# ATSAME54N19A device description
Architecture: CORTEX-M4; Family: SAMD; Series: SAME54
Registers are 32-bit, read-write, reset 0x0 unless marked. A register's access mark holds for its fields unless they carry their own. Offsets are from the block's base; [hi:lo] are bit positions; {n}, {i} and the like mark numbered series; 'fields as' and 'values as' point back to an identical list.

## CAN — Control Area Network
Instances: CAN0 0x42000000, CAN1 0x42000400
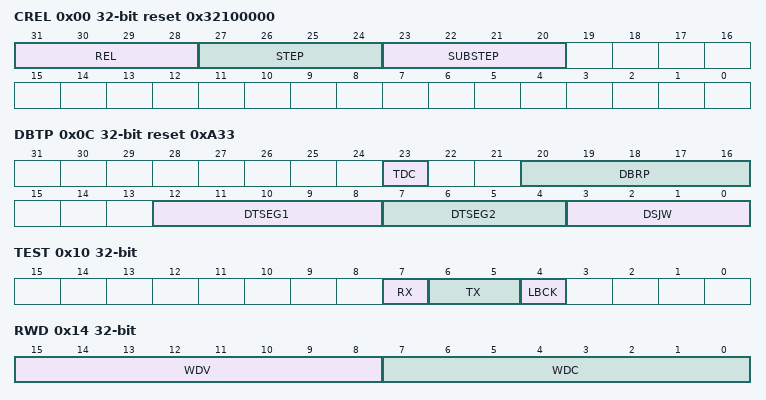
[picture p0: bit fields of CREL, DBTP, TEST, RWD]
0x00 CREL ro reset 0x32100000 — Core Release
  [31:28] REL — Core Release
  [27:24] STEP — Step of Core Release
  [23:20] SUBSTEP — Sub-step of Core Release
0x04 ENDN ro reset 0x87654321 — Endian
  [31:0] ETV — Endianness Test Value
0x08 MRCFG reset 0x2 — Message RAM Configuration
  [1:0] QOS — Quality of Service
    0=DISABLE (Background (no sensitive operation)); 1=LOW (Sensitive Bandwidth); 2=MEDIUM (Sensitive Latency); 3=HIGH (Critical Latency)
0x0C DBTP reset 0xA33 — Fast Bit Timing and Prescaler
  [23] TDC — Tranceiver Delay Compensation
  [20:16] DBRP — Data Baud Rate Prescaler
  [12:8] DTSEG1 — Data time segment before sample point
  [7:4] DTSEG2 — Data time segment after sample point
  [3:0] DSJW — Data (Re)Synchronization Jump Width
0x10 TEST
  [7] RX — Receive Pin
  [6:5] TX — Control of Transmit Pin
    0=CORE (TX controlled by CAN core); 1=SAMPLE (TX monitoring sample point); 2=DOMINANT (Dominant (0) level at pin CAN_TX); 3=RECESSIVE (Recessive (1) level at pin CAN_TX)
  [4] LBCK — Loop Back Mode
0x14 RWD — RAM Watchdog
  [15:8] WDV — Watchdog Value
  [7:0] WDC — Watchdog Configuration
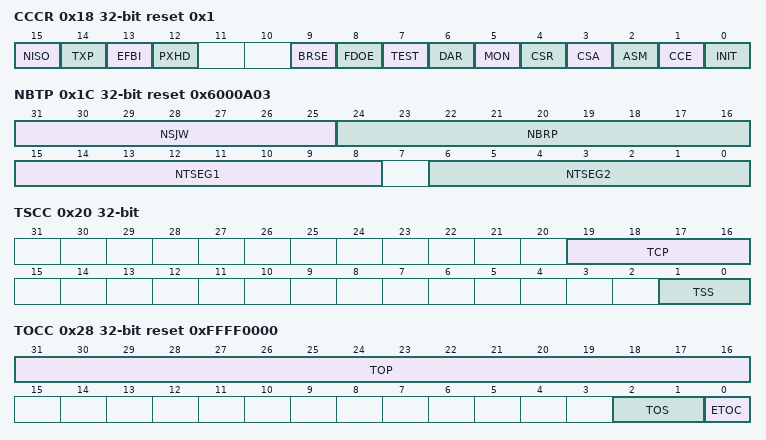
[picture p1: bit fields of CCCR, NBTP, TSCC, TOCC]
0x18 CCCR reset 0x1 (WSYNC) — CC Control
  [15] NISO — Non ISO Operation
  [14] TXP — Transmit Pause
  [13] EFBI — Edge Filtering during Bus Integration
  [12] PXHD — Protocol Exception Handling Disable
  [9] BRSE — Bit Rate Switch Enable
  [8] FDOE — FD Operation Enable
  [7] TEST — Test Mode Enable
  [6] DAR — Disable Automatic Retransmission
  [5] MON — Bus Monitoring Mode
  [4] CSR — Clock Stop Request
  [3] CSA — Clock Stop Acknowledge
  [2] ASM — ASM Restricted Operation Mode
  [1] CCE — Configuration Change Enable
  [0] INIT — Initialization
0x1C NBTP reset 0x6000A03 — Nominal Bit Timing and Prescaler
  [31:25] NSJW — Nominal (Re)Synchronization Jump Width
  [24:16] NBRP — Nominal Baud Rate Prescaler
  [15:8] NTSEG1 — Nominal Time segment before sample point
  [6:0] NTSEG2 — Nominal Time segment after sample point
0x20 TSCC — Timestamp Counter Configuration
  [19:16] TCP — Timestamp Counter Prescaler
  [1:0] TSS — Timestamp Select
    0=ZERO (Timestamp counter value always 0x0000); 1=INC (Timestamp counter value incremented by TCP); 2=EXT (External timestamp counter value used)
0x24 TSCV ro — Timestamp Counter Value
  [15:0] TSC — Timestamp Counter
0x28 TOCC reset 0xFFFF0000 — Timeout Counter Configuration
  [31:16] TOP — Timeout Period
  [2:1] TOS — Timeout Select
    0=CONT (Continuout operation); 1=TXEF (Timeout controlled by TX Event FIFO); 2=RXF0 (Timeout controlled by Rx FIFO 0); 3=RXF1 (Timeout controlled by Rx FIFO 1)
  [0] ETOC — Enable Timeout Counter
0x2C TOCV reset 0xFFFF — Timeout Counter Value
  [15:0] TOC — Timeout Counter
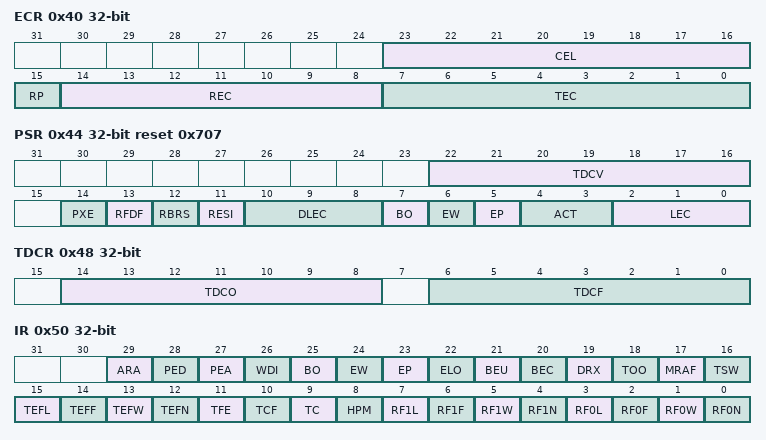
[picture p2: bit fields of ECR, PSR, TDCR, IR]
0x40 ECR ro — Error Counter
  [23:16] CEL — CAN Error Logging
  [15] RP — Receive Error Passive
  [14:8] REC — Receive Error Counter
  [7:0] TEC — Transmit Error Counter
0x44 PSR ro reset 0x707 — Protocol Status
  [22:16] TDCV — Transmitter Delay Compensation Value
  [14] PXE — Protocol Exception Event
  [13] RFDF — Received a CAN FD Message
  [12] RBRS — BRS flag of last received CAN FD Message
  [11] RESI — ESI flag of last received CAN FD Message
  [10:8] DLEC — Data Phase Last Error Code
    0=NONE (No Error); 1=STUFF (Stuff Error); 2=FORM (Form Error); 3=ACK (Ack Error); 4=BIT1 (Bit1 Error); 5=BIT0 (Bit0 Error); 6=CRC (CRC Error); 7=NC (No Change)
  [7] BO — Bus_Off Status
  [6] EW — Warning Status
  [5] EP — Error Passive
  [4:3] ACT — Activity
    0=SYNC (Node is synchronizing on CAN communication); 1=IDLE (Node is neither receiver nor transmitter); 2=RX (Node is operating as receiver); 3=TX (Node is operating as transmitter)
  [2:0] LEC — Last Error Code
    values as DLEC
0x48 TDCR — Extended ID Filter Configuration
  [14:8] TDCO — Transmitter Delay Compensation Offset
  [6:0] TDCF — Transmitter Delay Compensation Filter Length
0x50 IR — Interrupt
  [29] ARA — Access to Reserved Address
  [28] PED — Protocol Error in Data Phase
  [27] PEA — Protocol Error in Arbitration Phase
  [26] WDI — Watchdog Interrupt
  [25] BO — Bus_Off Status
  [24] EW — Warning Status
  [23] EP — Error Passive
  [22] ELO — Error Logging Overflow
  [21] BEU — Bit Error Uncorrected
  [20] BEC — Bit Error Corrected
  [19] DRX — Message stored to Dedicated Rx Buffer
  [18] TOO — Timeout Occurred
  [17] MRAF — Message RAM Access Failure
  [16] TSW — Timestamp Wraparound
  [15] TEFL — Tx Event FIFO Element Lost
  [14] TEFF — Tx Event FIFO Full
  [13] TEFW — Tx Event FIFO Watermark Reached
  [12] TEFN — Tx Event FIFO New Entry
  [11] TFE — Tx FIFO Empty
  [10] TCF — Transmission Cancellation Finished
  [9] TC — Timestamp Completed
  [8] HPM — High Priority Message
  [7] RF1L — Rx FIFO 1 Message Lost
  [6] RF1F — Rx FIFO 1 FIFO Full
  [5] RF1W — Rx FIFO 1 Watermark Reached
  [4] RF1N — Rx FIFO 1 New Message
  [3] RF0L — Rx FIFO 0 Message Lost
  [2] RF0F — Rx FIFO 0 Full
  [1] RF0W — Rx FIFO 0 Watermark Reached
  [0] RF0N — Rx FIFO 0 New Message
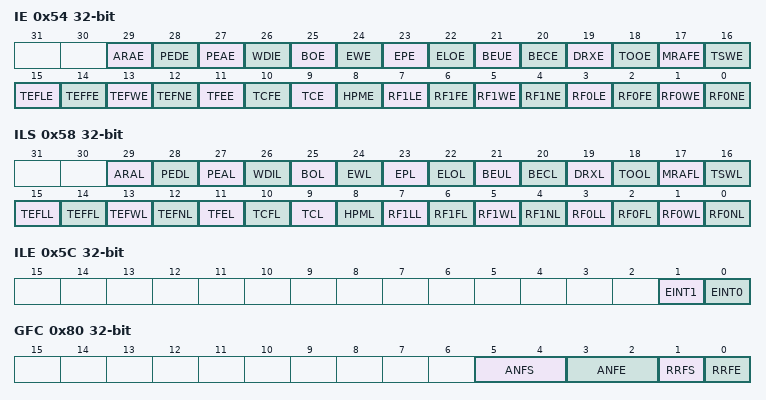
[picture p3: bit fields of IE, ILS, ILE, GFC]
0x54 IE — Interrupt Enable
  [29] ARAE — Access to Reserved Address Enable
  [28] PEDE — Protocol Error in Data Phase Enable
  [27] PEAE — Protocol Error in Arbitration Phase Enable
  [26] WDIE — Watchdog Interrupt Interrupt Enable
  [25] BOE — Bus_Off Status Interrupt Enable
  [24] EWE — Warning Status Interrupt Enable
  [23] EPE — Error Passive Interrupt Enable
  [22] ELOE — Error Logging Overflow Interrupt Enable
  [21] BEUE — Bit Error Uncorrected Interrupt Enable
  [20] BECE — Bit Error Corrected Interrupt Enable
  [19] DRXE — Message stored to Dedicated Rx Buffer Interrupt Enable
  [18] TOOE — Timeout Occurred Interrupt Enable
  [17] MRAFE — Message RAM Access Failure Interrupt Enable
  [16] TSWE — Timestamp Wraparound Interrupt Enable
  [15] TEFLE — Tx Event FIFO Element Lost Interrupt Enable
  [14] TEFFE — Tx Event FIFO Full Interrupt Enable
  [13] TEFWE — Tx Event FIFO Watermark Reached Interrupt Enable
  [12] TEFNE — Tx Event FIFO New Entry Interrupt Enable
  [11] TFEE — Tx FIFO Empty Interrupt Enable
  [10] TCFE — Transmission Cancellation Finished Interrupt Enable
  [9] TCE — Timestamp Completed Interrupt Enable
  [8] HPME — High Priority Message Interrupt Enable
  [7] RF1LE — Rx FIFO 1 Message Lost Interrupt Enable
  [6] RF1FE — Rx FIFO 1 FIFO Full Interrupt Enable
  [5] RF1WE — Rx FIFO 1 Watermark Reached Interrupt Enable
  [4] RF1NE — Rx FIFO 1 New Message Interrupt Enable
  [3] RF0LE — Rx FIFO 0 Message Lost Interrupt Enable
  [2] RF0FE — Rx FIFO 0 Full Interrupt Enable
  [1] RF0WE — Rx FIFO 0 Watermark Reached Interrupt Enable
  [0] RF0NE — Rx FIFO 0 New Message Interrupt Enable
0x58 ILS — Interrupt Line Select
  [29] ARAL — Access to Reserved Address Line
  [28] PEDL — Protocol Error in Data Phase Line
  [27] PEAL — Protocol Error in Arbitration Phase Line
  [26] WDIL — Watchdog Interrupt Interrupt Line
  [25] BOL — Bus_Off Status Interrupt Line
  [24] EWL — Warning Status Interrupt Line
  [23] EPL — Error Passive Interrupt Line
  [22] ELOL — Error Logging Overflow Interrupt Line
  [21] BEUL — Bit Error Uncorrected Interrupt Line
  [20] BECL — Bit Error Corrected Interrupt Line
  [19] DRXL — Message stored to Dedicated Rx Buffer Interrupt Line
  [18] TOOL — Timeout Occurred Interrupt Line
  [17] MRAFL — Message RAM Access Failure Interrupt Line
  [16] TSWL — Timestamp Wraparound Interrupt Line
  [15] TEFLL — Tx Event FIFO Element Lost Interrupt Line
  [14] TEFFL — Tx Event FIFO Full Interrupt Line
  [13] TEFWL — Tx Event FIFO Watermark Reached Interrupt Line
  [12] TEFNL — Tx Event FIFO New Entry Interrupt Line
  [11] TFEL — Tx FIFO Empty Interrupt Line
  [10] TCFL — Transmission Cancellation Finished Interrupt Line
  [9] TCL — Timestamp Completed Interrupt Line
  [8] HPML — High Priority Message Interrupt Line
  [7] RF1LL — Rx FIFO 1 Message Lost Interrupt Line
  [6] RF1FL — Rx FIFO 1 FIFO Full Interrupt Line
  [5] RF1WL — Rx FIFO 1 Watermark Reached Interrupt Line
  [4] RF1NL — Rx FIFO 1 New Message Interrupt Line
  [3] RF0LL — Rx FIFO 0 Message Lost Interrupt Line
  [2] RF0FL — Rx FIFO 0 Full Interrupt Line
  [1] RF0WL — Rx FIFO 0 Watermark Reached Interrupt Line
  [0] RF0NL — Rx FIFO 0 New Message Interrupt Line
0x5C ILE — Interrupt Line Enable
  [1] EINT1 — Enable Interrupt Line 1
  [0] EINT0 — Enable Interrupt Line 0
0x80 GFC — Global Filter Configuration
  [5:4] ANFS — Accept Non-matching Frames Standard
    0=RXF0 (Accept in Rx FIFO 0); 1=RXF1 (Accept in Rx FIFO 1); 2=REJECT
  [3:2] ANFE — Accept Non-matching Frames Extended
    values as ANFS
  [1] RRFS — Reject Remote Frames Standard
  [0] RRFE — Reject Remote Frames Extended
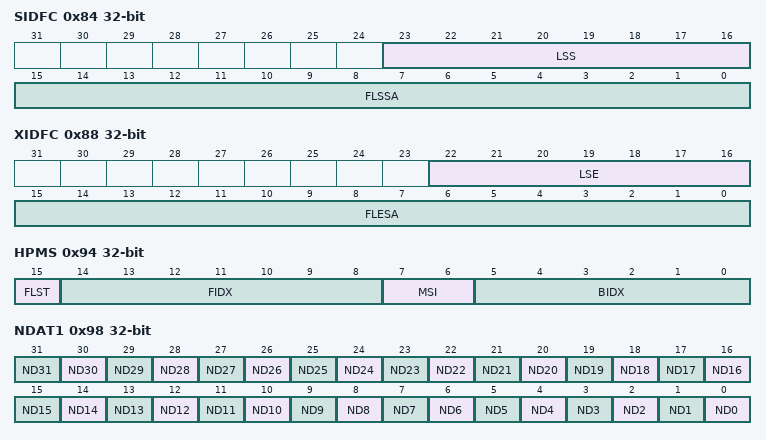
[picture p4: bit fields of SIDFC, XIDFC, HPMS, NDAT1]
0x84 SIDFC — Standard ID Filter Configuration
  [23:16] LSS — List Size Standard
  [15:0] FLSSA — Filter List Standard Start Address
0x88 XIDFC — Extended ID Filter Configuration
  [22:16] LSE — List Size Extended
  [15:0] FLESA — Filter List Extended Start Address
0x90 XIDAM reset 0x1FFFFFFF — Extended ID AND Mask
  [28:0] EIDM — Extended ID Mask
0x94 HPMS ro — High Priority Message Status
  [15] FLST — Filter List
  [14:8] FIDX — Filter Index
  [7:6] MSI — Message Storage Indicator
    0=NONE (No FIFO selected); 1=LOST (FIFO message lost); 2=FIFO0 (Message stored in FIFO 0); 3=FIFO1 (Message stored in FIFO 1)
  [5:0] BIDX — Buffer Index
0x98 NDAT1 — New Data 1
  [n] ND{n} (n=0..31) — New Data {n}
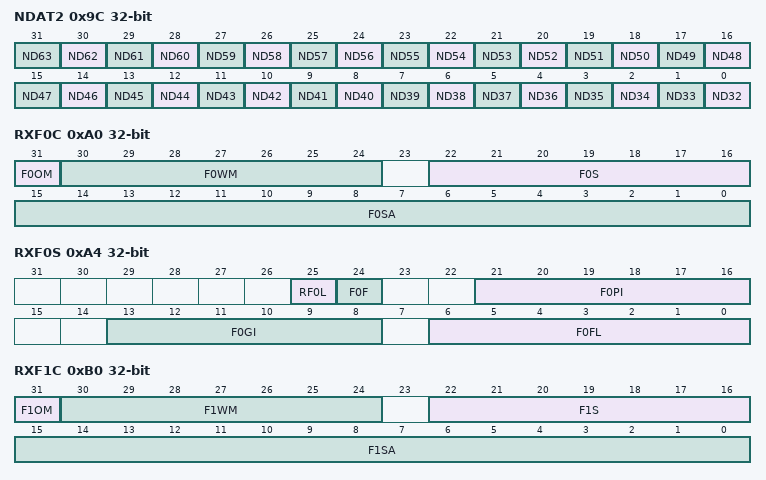
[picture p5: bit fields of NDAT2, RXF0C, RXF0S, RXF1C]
0x9C NDAT2 — New Data 2
  [n-32] ND{n} (n=32..63) — New Data {n}
0xA0 RXF0C — Rx FIFO 0 Configuration
  [31] F0OM — FIFO 0 Operation Mode
  [30:24] F0WM — Rx FIFO 0 Watermark
  [22:16] F0S — Rx FIFO 0 Size
  [15:0] F0SA — Rx FIFO 0 Start Address
0xA4 RXF0S ro — Rx FIFO 0 Status
  [25] RF0L — Rx FIFO 0 Message Lost
  [24] F0F — Rx FIFO 0 Full
  [21:16] F0PI — Rx FIFO 0 Put Index
  [13:8] F0GI — Rx FIFO 0 Get Index
  [6:0] F0FL — Rx FIFO 0 Fill Level
0xA8 RXF0A — Rx FIFO 0 Acknowledge
  [5:0] F0AI — Rx FIFO 0 Acknowledge Index
0xAC RXBC — Rx Buffer Configuration
  [15:0] RBSA — Rx Buffer Start Address
0xB0 RXF1C — Rx FIFO 1 Configuration
  [31] F1OM — FIFO 1 Operation Mode
  [30:24] F1WM — Rx FIFO 1 Watermark
  [22:16] F1S — Rx FIFO 1 Size
  [15:0] F1SA — Rx FIFO 1 Start Address
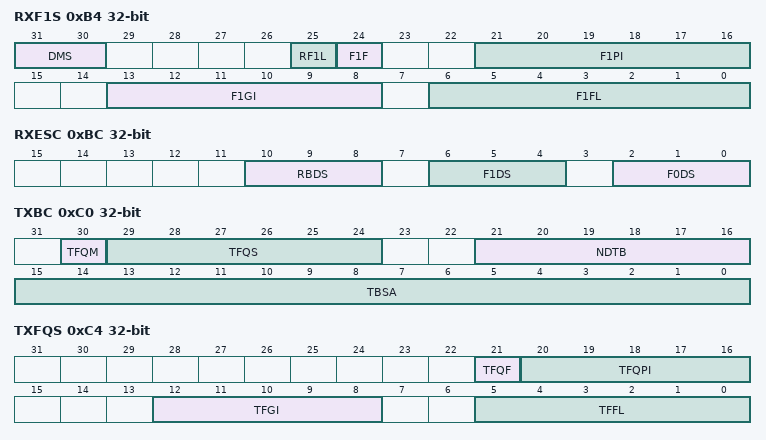
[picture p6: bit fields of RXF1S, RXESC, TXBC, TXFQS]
0xB4 RXF1S ro — Rx FIFO 1 Status
  [31:30] DMS — Debug Message Status
    0=IDLE (Idle state); 1=DBGA (Debug message A received); 2=DBGB (Debug message A/B received); 3=DBGC (Debug message A/B/C received, DMA request set)
  [25] RF1L — Rx FIFO 1 Message Lost
  [24] F1F — Rx FIFO 1 Full
  [21:16] F1PI — Rx FIFO 1 Put Index
  [13:8] F1GI — Rx FIFO 1 Get Index
  [6:0] F1FL — Rx FIFO 1 Fill Level
0xB8 RXF1A — Rx FIFO 1 Acknowledge
  [5:0] F1AI — Rx FIFO 1 Acknowledge Index
0xBC RXESC — Rx Buffer / FIFO Element Size Configuration
  [all] fields
    0=DATA8 (8 byte data field); 1=DATA12 (12 byte data field); 2=DATA16 (16 byte data field); 3=DATA20 (20 byte data field); 4=DATA24 (24 byte data field); 5=DATA32 (32 byte data field); 6=DATA48 (48 byte data field); 7=DATA64 (64 byte data field)
  [10:8] RBDS — Rx Buffer Data Field Size
  [6:4] F1DS — Rx FIFO 1 Data Field Size
  [2:0] F0DS — Rx FIFO 0 Data Field Size
0xC0 TXBC — Tx Buffer Configuration
  [30] TFQM — Tx FIFO/Queue Mode
  [29:24] TFQS — Transmit FIFO/Queue Size
  [21:16] NDTB — Number of Dedicated Transmit Buffers
  [15:0] TBSA — Tx Buffers Start Address
0xC4 TXFQS ro — Tx FIFO / Queue Status
  [21] TFQF — Tx FIFO/Queue Full
  [20:16] TFQPI — Tx FIFO/Queue Put Index
  [12:8] TFGI — Tx FIFO Get Index
  [5:0] TFFL — Tx FIFO Free Level
0xC8 TXESC — Tx Buffer Element Size Configuration
  [2:0] TBDS — Tx Buffer Data Field Size
    values as the fields of RXESC
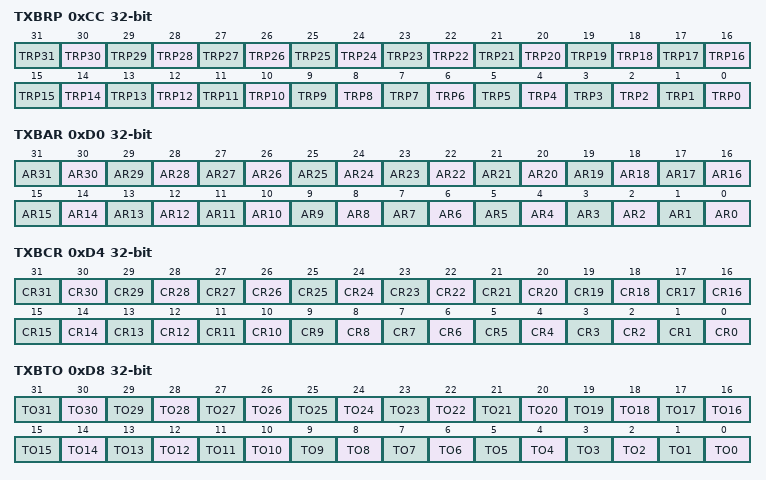
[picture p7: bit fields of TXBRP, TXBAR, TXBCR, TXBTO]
0xCC TXBRP ro — Tx Buffer Request Pending
  [n] TRP{n} (n=0..31) — Transmission Request Pending {n}
0xD0 TXBAR — Tx Buffer Add Request
  [n] AR{n} (n=0..31) — Add Request {n}
0xD4 TXBCR — Tx Buffer Cancellation Request
  [n] CR{n} (n=0..31) — Cancellation Request {n}
0xD8 TXBTO ro — Tx Buffer Transmission Occurred
  [n] TO{n} (n=0..31) — Transmission Occurred {n}
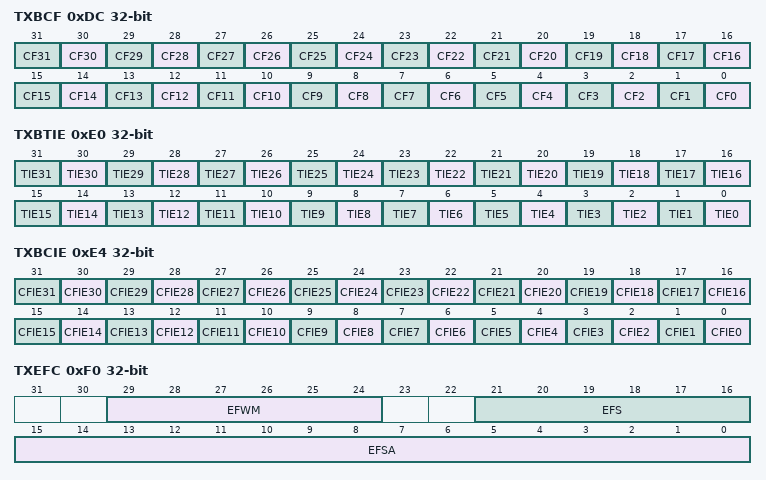
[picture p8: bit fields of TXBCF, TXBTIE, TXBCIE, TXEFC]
0xDC TXBCF ro — Tx Buffer Cancellation Finished
  [n] CF{n} (n=0..31) — Tx Buffer Cancellation Finished {n}
0xE0 TXBTIE — Tx Buffer Transmission Interrupt Enable
  [n] TIE{n} (n=0..31) — Transmission Interrupt Enable {n}
0xE4 TXBCIE — Tx Buffer Cancellation Finished Interrupt Enable
  [n] CFIE{n} (n=0..31) — Cancellation Finished Interrupt Enable {n}
0xF0 TXEFC — Tx Event FIFO Configuration
  [29:24] EFWM — Event FIFO Watermark
  [21:16] EFS — Event FIFO Size
  [15:0] EFSA — Event FIFO Start Address
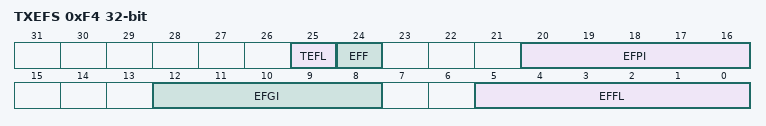
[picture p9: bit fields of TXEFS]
0xF4 TXEFS ro — Tx Event FIFO Status
  [25] TEFL — Tx Event FIFO Element Lost
  [24] EFF — Event FIFO Full
  [20:16] EFPI — Event FIFO Put Index
  [12:8] EFGI — Event FIFO Get Index
  [5:0] EFFL — Event FIFO Fill Level
0xF8 TXEFA — Tx Event FIFO Acknowledge
  [4:0] EFAI — Event FIFO Acknowledge Index
Value list CAN_SIDFE_0__SFEC: 0=DISABLE (Disable filter element); 1=STF0M (Store in Rx FIFO 0 if filter match); 2=STF1M (Store in Rx FIFO 1 if filter match); 3=REJECT (Reject ID if filter match); 4=PRIORITY (Set priority if filter match); 5=PRIF0M (Set priority and store in FIFO 0 if filter match); 6=PRIF1M (Set priority and store in FIFO 1 if filter match); 7=STRXBUF (Store into Rx Buffer)
Value list CAN_SIDFE_0__SFT: 0=RANGE (Range filter from SFID1 to SFID2); 1=DUAL (Dual ID filter for SFID1 or SFID2); 2=CLASSIC (Classic filter)
Value list CAN_TXEFE_1__ET: 1=TXE (Tx event); 2=TXC (Transmission in spite of cancellation)
Value list CAN_XIDFE_1__EFT: 0=RANGEM (Range filter from EFID1 to EFID2); 1=DUAL (Dual ID filter for EFID1 or EFID2); 2=CLASSIC (Classic filter); 3=RANGE (Range filter from EFID1 to EFID2 with no XIDAM mask)

## Notices in the file
Copyright (c) 2017 Atmel Corporation,
a wholly owned subsidiary of Microchip Technology Inc.
Licensed under the Apache License, Version 2.0 (the "License");
you may not use this file except in compliance with the License.
You may obtain a copy of the Licence at
http://www.apache.org/licenses/LICENSE-2.0
Unless required by applicable law or agreed to in writing, software
distributed under the License is distributed on an "AS IS" BASIS,
WITHOUT WARRANTIES OR CONDITIONS OF ANY KIND, either express or implied.
See the License for the specific language governing permissions and
limitations under the License.
